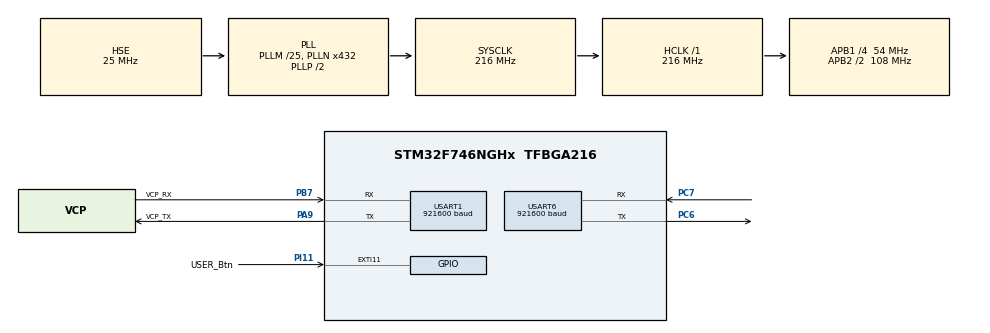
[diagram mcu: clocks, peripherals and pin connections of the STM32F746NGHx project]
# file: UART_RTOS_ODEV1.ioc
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CORTEX_M7.CPU_DCache=Disabled
CORTEX_M7.CPU_ICache=Enabled
Dma.Request0=USART1_TX
Dma.Request1=USART6_TX
Dma.Request2=USART6_RX
Dma.Request3=USART1_RX
Dma.USART1_RX.3.Direction=DMA_PERIPH_TO_MEMORY
Dma.USART1_RX.3.FIFOMode=DMA_FIFOMODE_DISABLE
Dma.USART1_RX.3.Instance=DMA2_Stream2
Dma.USART1_RX.3.MemDataAlignment=DMA_MDATAALIGN_BYTE
Dma.USART1_RX.3.MemInc=DMA_MINC_ENABLE
Dma.USART1_RX.3.Mode=DMA_CIRCULAR
Dma.USART1_RX.3.PeriphDataAlignment=DMA_PDATAALIGN_BYTE
Dma.USART1_RX.3.PeriphInc=DMA_PINC_DISABLE
Dma.USART1_RX.3.Priority=DMA_PRIORITY_LOW
Dma.USART1_TX.0.Direction=DMA_MEMORY_TO_PERIPH
Dma.USART1_TX.0.FIFOMode=DMA_FIFOMODE_DISABLE
Dma.USART1_TX.0.Instance=DMA2_Stream7
Dma.USART1_TX.0.MemDataAlignment=DMA_MDATAALIGN_BYTE
Dma.USART1_TX.0.MemInc=DMA_MINC_ENABLE
Dma.USART1_TX.0.Mode=DMA_NORMAL
Dma.USART1_TX.0.PeriphDataAlignment=DMA_PDATAALIGN_BYTE
Dma.USART1_TX.0.PeriphInc=DMA_PINC_DISABLE
Dma.USART1_TX.0.Priority=DMA_PRIORITY_LOW
Dma.USART6_RX.2.Direction=DMA_PERIPH_TO_MEMORY
Dma.USART6_RX.2.FIFOMode=DMA_FIFOMODE_DISABLE
Dma.USART6_RX.2.Instance=DMA2_Stream1
Dma.USART6_RX.2.MemDataAlignment=DMA_MDATAALIGN_BYTE
Dma.USART6_RX.2.MemInc=DMA_MINC_ENABLE
Dma.USART6_RX.2.Mode=DMA_NORMAL
Dma.USART6_RX.2.PeriphDataAlignment=DMA_PDATAALIGN_BYTE
Dma.USART6_RX.2.PeriphInc=DMA_PINC_DISABLE
Dma.USART6_RX.2.Priority=DMA_PRIORITY_LOW
Dma.USART6_TX.1.Direction=DMA_MEMORY_TO_PERIPH
Dma.USART6_TX.1.FIFOMode=DMA_FIFOMODE_DISABLE
Dma.USART6_TX.1.Instance=DMA2_Stream6
Dma.USART6_TX.1.MemDataAlignment=DMA_MDATAALIGN_BYTE
Dma.USART6_TX.1.MemInc=DMA_MINC_ENABLE
Dma.USART6_TX.1.Mode=DMA_NORMAL
Dma.USART6_TX.1.PeriphDataAlignment=DMA_PDATAALIGN_BYTE
Dma.USART6_TX.1.PeriphInc=DMA_PINC_DISABLE
Dma.USART6_TX.1.Priority=DMA_PRIORITY_LOW
FREERTOS.INCLUDE_uxTaskGetStackHighWaterMark=1
FREERTOS.Tasks01=defaultTask,24,128,StartDefaultTask,Default,NULL,Dynamic,NULL,NULL
FREERTOS.configCHECK_FOR_STACK_OVERFLOW=2
FREERTOS.configTOTAL_HEAP_SIZE=25600
FREERTOS.configUSE_MALLOC_FAILED_HOOK=1
FREERTOS.configUSE_NEWLIB_REENTRANT=1
Mcu.Family=STM32F7
Mcu.Name=STM32F746NGHx
Mcu.Package=TFBGA216
NVIC.DMA2_Stream1_IRQn=true\:5\:0\:false\:false\:true\:true\:false\:true\:true
NVIC.DMA2_Stream2_IRQn=true\:5\:0\:false\:false\:true\:true\:false\:true\:true
NVIC.DMA2_Stream6_IRQn=true\:5\:0\:false\:false\:true\:true\:false\:true\:true
NVIC.DMA2_Stream7_IRQn=true\:5\:0\:false\:false\:true\:true\:false\:true\:true
NVIC.EXTI15_10_IRQn=true\:5\:0\:false\:false\:true\:true\:true\:true\:true
NVIC.PriorityGroup=NVIC_PRIORITYGROUP_4
NVIC.RCC_IRQn=true\:5\:0\:false\:false\:true\:true\:true\:false\:true
NVIC.TIM6_DAC_IRQn=true\:15\:0\:false\:false\:true\:false\:false\:true\:true
NVIC.TimeBase=TIM6_DAC_IRQn
NVIC.TimeBaseIP=TIM6
NVIC.USART1_IRQn=true\:5\:0\:false\:false\:true\:true\:true\:true\:true
NVIC.USART6_IRQn=true\:5\:0\:false\:false\:true\:true\:true\:true\:true
PA13.Mode=Serial_Wire
PA13.Signal=SYS_JTMS-SWDIO
PA14.Mode=Serial_Wire
PA14.Signal=SYS_JTCK-SWCLK
PA9.GPIO_Label=VCP_TX
PA9.Mode=Asynchronous
PA9.Signal=USART1_TX
PB7.GPIO_Label=VCP_RX
PB7.Mode=Asynchronous
PB7.Signal=USART1_RX
PC14/OSC32_IN.Mode=LSE-External-Oscillator
PC14/OSC32_IN.Signal=RCC_OSC32_IN
PC15/OSC32_OUT.Mode=LSE-External-Oscillator
PC15/OSC32_OUT.Signal=RCC_OSC32_OUT
PC6.Mode=Asynchronous
PC6.Signal=USART6_TX
PC7.Mode=Asynchronous
PC7.Signal=USART6_RX
PH0/OSC_IN.Mode=HSE-External-Oscillator
PH0/OSC_IN.Signal=RCC_OSC_IN
PH1/OSC_OUT.Mode=HSE-External-Oscillator
PH1/OSC_OUT.Signal=RCC_OSC_OUT
PI11.GPIO_Label=USER_Btn
PI11.GPIO_ModeDefaultEXTI=GPIO_MODE_IT_RISING_FALLING
PI11.GPIO_PuPd=GPIO_NOPULL
PI11.Signal=GPXTI11
ProjectManager.HeapSize=0x200
ProjectManager.StackSize=0x400
ProjectManager.TargetToolchain=STM32CubeIDE
RCC.AHBFreq_Value=216000000
RCC.APB1CLKDivider=RCC_HCLK_DIV4
RCC.APB1Freq_Value=54000000
RCC.APB1TimFreq_Value=108000000
RCC.APB2CLKDivider=RCC_HCLK_DIV2
RCC.APB2Freq_Value=108000000
RCC.APB2TimFreq_Value=216000000
RCC.CortexFreq_Value=216000000
RCC.HCLKFreq_Value=216000000
RCC.HSE_VALUE=25000000
RCC.HSI_VALUE=16000000
RCC.PLL48CLockSelection=RCC_CLK48SOURCE_PLLSAIP
RCC.PLLI2SN=100
RCC.PLLM=25
RCC.PLLN=432
RCC.PLLQ=9
RCC.PLLSAIP=RCC_PLLSAIP_DIV4
RCC.PLLSAIRDiv=RCC_PLLSAIDIVR_4
RCC.PLLSourceVirtual=RCC_PLLSOURCE_HSE
RCC.SDMMCClockSelection=RCC_SDMMC1CLKSOURCE_CLK48
RCC.SYSCLKFreq_VALUE=216000000
RCC.SYSCLKSource=RCC_SYSCLKSOURCE_PLLCLK
RCC.USBFreq_Value=48000000
RCC.VCOOutputFreq_Value=432000000
USART1.BaudRate=921600
USART1.Mode=MODE_TX_RX
USART1.OverSampling=UART_OVERSAMPLING_16
USART1.Parity=PARITY_NONE
USART1.StopBits=STOPBITS_1
USART1.VirtualMode-Asynchronous=VM_ASYNC
USART1.WordLength=WORDLENGTH_8B
USART6.BaudRate=921600
USART6.VirtualMode-Asynchronous=VM_ASYNC
VP_FREERTOS_VS_CMSIS_V2.Mode=CMSIS_V2
VP_SYS_VS_tim6.Mode=TIM6
board=STM32F746G-DISCO

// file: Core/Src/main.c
/* USER CODE BEGIN Header */
/**
  ******************************************************************************
  * @file           : main.c
  * @brief          : Main program body
  ******************************************************************************
  * @attention
  *
  * Copyright (c) 2026 STMicroelectronics.
  * All rights reserved.
  *
  * This software is licensed under terms that can be found in the LICENSE file
  * in the root directory of this software component.
  * If no LICENSE file comes with this software, it is provided AS-IS.
  *
  ******************************************************************************
  */
/* USER CODE END Header */
#include "main.h"
#include "cmsis_os.h"

/* USER CODE BEGIN Includes */
#include "app_trace.h"
#include "app_timestamp.h"
#include "app_rtos.h"
/* USER CODE END Includes */

UART_HandleTypeDef huart1;
UART_HandleTypeDef huart6;
DMA_HandleTypeDef hdma_usart1_tx;
DMA_HandleTypeDef hdma_usart1_rx;
DMA_HandleTypeDef hdma_usart6_tx;
DMA_HandleTypeDef hdma_usart6_rx;

/* Definitions for defaultTask */
osThreadId_t defaultTaskHandle;
const osThreadAttr_t defaultTask_attributes = {
  .name = "defaultTask",
  .stack_size = 128 * 4,
  .priority = (osPriority_t) osPriorityNormal,
};

void SystemClock_Config(void);
static void MX_GPIO_Init(void);
static void MX_DMA_Init(void);
static void MX_USART1_UART_Init(void);
static void MX_USART6_UART_Init(void);
void StartDefaultTask(void *argument);

int main(void)
{

  /* Enable the CPU Cache */

  /* Enable I-Cache---------------------------------------------------------*/
  SCB_EnableICache();

  /* MCU Configuration--------------------------------------------------------*/

  /* Reset of all peripherals, Initializes the Flash interface and the Systick. */
  HAL_Init();

  /* Configure the system clock */
  SystemClock_Config();

  /* Initialize all configured peripherals */
  MX_GPIO_Init();
  MX_DMA_Init();
  MX_USART1_UART_Init();
  MX_USART6_UART_Init();
  /* USER CODE BEGIN 2 */
  g_dwt_ok = Timestamp_Init();

  /* USER CODE END 2 */

  /* Init scheduler */
  osKernelInitialize();

  /* USER CODE BEGIN RTOS_MUTEX */
  App_Trace_Init(); /* Before creating application tasks and queues. */
  /* add mutexes, ... */
  /* USER CODE END RTOS_MUTEX */

  /* Create the thread(s) */
  /* creation of defaultTask */
  defaultTaskHandle = osThreadNew(StartDefaultTask, NULL, &defaultTask_attributes);

  /* USER CODE BEGIN RTOS_THREADS */
  App_RTOS_Init();   /* kuyruklar, semaphore, event flag + UartTxTask/ButtonTask/TelemetryTask */
  /* USER CODE END RTOS_THREADS */

  /* Start scheduler */
  osKernelStart();

  /* We should never get here as control is now taken by the scheduler */

  /* Infinite loop */
  while (1)
  {

  }
}

void SystemClock_Config(void)
{
  RCC_OscInitTypeDef RCC_OscInitStruct = {0};
  RCC_ClkInitTypeDef RCC_ClkInitStruct = {0};

  /** Configure LSE Drive Capability
  */
  HAL_PWR_EnableBkUpAccess();

  /** Configure the main internal regulator output voltage
  */
  __HAL_RCC_PWR_CLK_ENABLE();
  __HAL_PWR_VOLTAGESCALING_CONFIG(PWR_REGULATOR_VOLTAGE_SCALE1);

  /** Initializes the RCC Oscillators according to the specified parameters
  * in the RCC_OscInitTypeDef structure.
  */
  RCC_OscInitStruct.OscillatorType = RCC_OSCILLATORTYPE_HSE;
  RCC_OscInitStruct.HSEState = RCC_HSE_ON;
  RCC_OscInitStruct.PLL.PLLState = RCC_PLL_ON;
  RCC_OscInitStruct.PLL.PLLSource = RCC_PLLSOURCE_HSE;
  RCC_OscInitStruct.PLL.PLLM = 25;
  RCC_OscInitStruct.PLL.PLLN = 432;
  RCC_OscInitStruct.PLL.PLLP = RCC_PLLP_DIV2;
  RCC_OscInitStruct.PLL.PLLQ = 9;
  if (HAL_RCC_OscConfig(&RCC_OscInitStruct) != HAL_OK)
  {
    Error_Handler();
  }

  /** Activate the Over-Drive mode
  */
  if (HAL_PWREx_EnableOverDrive() != HAL_OK)
  {
    Error_Handler();
  }

  /** Initializes the CPU, AHB and APB buses clocks
  */
  RCC_ClkInitStruct.ClockType = RCC_CLOCKTYPE_HCLK|RCC_CLOCKTYPE_SYSCLK
                              |RCC_CLOCKTYPE_PCLK1|RCC_CLOCKTYPE_PCLK2;
  RCC_ClkInitStruct.SYSCLKSource = RCC_SYSCLKSOURCE_PLLCLK;
  RCC_ClkInitStruct.AHBCLKDivider = RCC_SYSCLK_DIV1;
  RCC_ClkInitStruct.APB1CLKDivider = RCC_HCLK_DIV4;
  RCC_ClkInitStruct.APB2CLKDivider = RCC_HCLK_DIV2;

  if (HAL_RCC_ClockConfig(&RCC_ClkInitStruct, FLASH_LATENCY_7) != HAL_OK)
  {
    Error_Handler();
  }
}

static void MX_USART1_UART_Init(void)
{

  huart1.Instance = USART1;
  huart1.Init.BaudRate = 921600;
  huart1.Init.WordLength = UART_WORDLENGTH_8B;
  huart1.Init.StopBits = UART_STOPBITS_1;
  huart1.Init.Parity = UART_PARITY_NONE;
  huart1.Init.Mode = UART_MODE_TX_RX;
  huart1.Init.HwFlowCtl = UART_HWCONTROL_NONE;
  huart1.Init.OverSampling = UART_OVERSAMPLING_16;
  huart1.Init.OneBitSampling = UART_ONE_BIT_SAMPLE_DISABLE;
  huart1.AdvancedInit.AdvFeatureInit = UART_ADVFEATURE_NO_INIT;
  if (HAL_UART_Init(&huart1) != HAL_OK)
  {
    Error_Handler();
  }

}

static void MX_USART6_UART_Init(void)
{

  huart6.Instance = USART6;
  huart6.Init.BaudRate = 921600;
  huart6.Init.WordLength = UART_WORDLENGTH_8B;
  huart6.Init.StopBits = UART_STOPBITS_1;
  huart6.Init.Parity = UART_PARITY_NONE;
  huart6.Init.Mode = UART_MODE_TX_RX;
  huart6.Init.HwFlowCtl = UART_HWCONTROL_NONE;
  huart6.Init.OverSampling = UART_OVERSAMPLING_16;
  huart6.Init.OneBitSampling = UART_ONE_BIT_SAMPLE_DISABLE;
  huart6.AdvancedInit.AdvFeatureInit = UART_ADVFEATURE_NO_INIT;
  if (HAL_UART_Init(&huart6) != HAL_OK)
  {
    Error_Handler();
  }

}

static void MX_DMA_Init(void)
{

  /* DMA controller clock enable */
  __HAL_RCC_DMA2_CLK_ENABLE();

  /* DMA interrupt init */
  /* DMA2_Stream1_IRQn interrupt configuration */
  HAL_NVIC_SetPriority(DMA2_Stream1_IRQn, 5, 0);
  HAL_NVIC_EnableIRQ(DMA2_Stream1_IRQn);
  /* DMA2_Stream2_IRQn interrupt configuration */
  HAL_NVIC_SetPriority(DMA2_Stream2_IRQn, 5, 0);
  HAL_NVIC_EnableIRQ(DMA2_Stream2_IRQn);
  /* DMA2_Stream6_IRQn interrupt configuration */
  HAL_NVIC_SetPriority(DMA2_Stream6_IRQn, 5, 0);
  HAL_NVIC_EnableIRQ(DMA2_Stream6_IRQn);
  /* DMA2_Stream7_IRQn interrupt configuration */
  HAL_NVIC_SetPriority(DMA2_Stream7_IRQn, 5, 0);
  HAL_NVIC_EnableIRQ(DMA2_Stream7_IRQn);

}

static void MX_GPIO_Init(void)
{
  GPIO_InitTypeDef GPIO_InitStruct = {0};

  /* GPIO Ports Clock Enable */
  __HAL_RCC_GPIOA_CLK_ENABLE();
  __HAL_RCC_GPIOB_CLK_ENABLE();
  __HAL_RCC_GPIOC_CLK_ENABLE();
  __HAL_RCC_GPIOI_CLK_ENABLE();
  __HAL_RCC_GPIOH_CLK_ENABLE();

  /*Configure GPIO pin : USER_Btn_Pin */
  GPIO_InitStruct.Pin = USER_Btn_Pin;
  GPIO_InitStruct.Mode = GPIO_MODE_IT_RISING_FALLING;
  GPIO_InitStruct.Pull = GPIO_NOPULL;
  HAL_GPIO_Init(USER_Btn_GPIO_Port, &GPIO_InitStruct);

  /* EXTI interrupt init*/
  HAL_NVIC_SetPriority(EXTI15_10_IRQn, 5, 0);
  HAL_NVIC_EnableIRQ(EXTI15_10_IRQn);

}

void StartDefaultTask(void *argument)
{
  for(;;)
  {
    osDelay(1);
  }
}

void HAL_TIM_PeriodElapsedCallback(TIM_HandleTypeDef *htim)
{
  if (htim->Instance == TIM6) {
    HAL_IncTick();
  }
}

void Error_Handler(void)
{
  __disable_irq();
  while (1)
  {
  }
}
